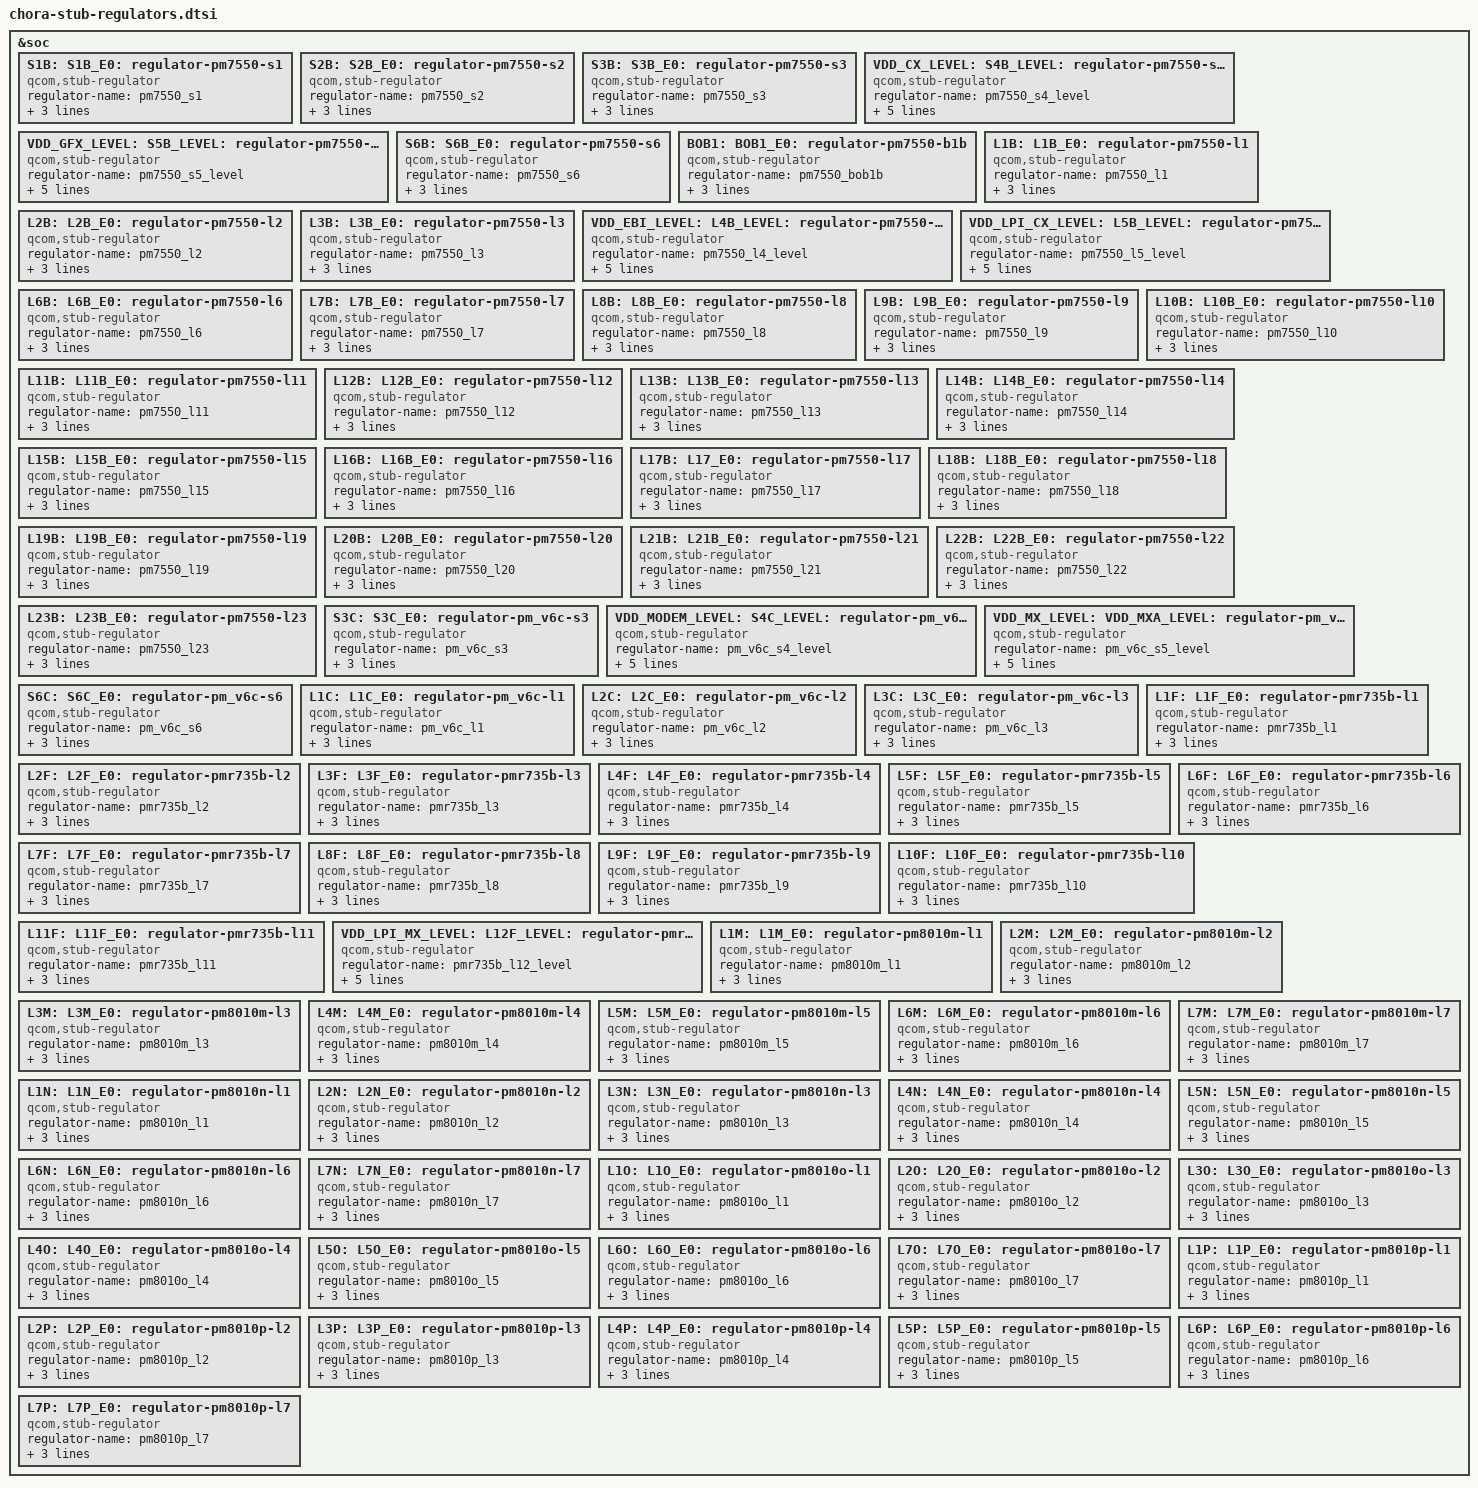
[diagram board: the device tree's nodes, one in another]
// SPDX-License-Identifier: BSD-3-Clause
/*
 * Copyright (c) Qualcomm Technologies, Inc. and/or its subsidiaries.
 */

#include <dt-bindings/regulator/qcom,rpmh-regulator-levels.h>

&soc {
		S1B:
		S1B_E0:
		pm7550_s1: regulator-pm7550-s1 {
			compatible = "qcom,stub-regulator";
			regulator-name = "pm7550_s1";
			qcom,hpm-min-load = <10000>;
			regulator-min-microvolt = <1856000>;
			regulator-max-microvolt = <2040000>;
		};

		S2B:
		S2B_E0:
		pm7550_s2: regulator-pm7550-s2 {
			compatible = "qcom,stub-regulator";
			regulator-name = "pm7550_s2";
			qcom,hpm-min-load = <10000>;
			regulator-min-microvolt = <1020000>;
			regulator-max-microvolt = <2100000>;
		};

		S3B:
		S3B_E0:
		pm7550_s3: regulator-pm7550-s3 {
			compatible = "qcom,stub-regulator";
			regulator-name = "pm7550_s3";
			qcom,hpm-min-load = <10000>;
			regulator-min-microvolt = <375000>;
			regulator-max-microvolt = <2744000>;
		};

		VDD_CX_LEVEL:
		S4B_LEVEL:
		S4B_E0_LEVEL:
		VDD_CX_LEVEL_AO:
		S4B_LEVEL_A0:
		pm7550_s4_level: regulator-pm7550-s4-level {
			compatible = "qcom,stub-regulator";
			regulator-name = "pm7550_s4_level";
			qcom,hpm-min-load = <10000>;
			regulator-min-microvolt =
				<RPMH_REGULATOR_LEVEL_RETENTION>;
			regulator-max-microvolt = <RPMH_REGULATOR_LEVEL_MAX>;
		};

		VDD_GFX_LEVEL:
		S5B_LEVEL:
		S5B_E0_LEVEL:
		pm7550_s5_level: regulator-pm7550-s5-level {
			compatible = "qcom,stub-regulator";
			regulator-name = "pm7550_s5_level";
			qcom,hpm-min-load = <10000>;
			regulator-min-microvolt =
				<RPMH_REGULATOR_LEVEL_RETENTION>;
			regulator-max-microvolt = <RPMH_REGULATOR_LEVEL_MAX>;
		};

		S6B:
		S6B_E0:
		pm7550_s6: regulator-pm7550-s6 {
			compatible = "qcom,stub-regulator";
			regulator-name = "pm7550_s6";
			qcom,hpm-min-load = <10000>;
			regulator-min-microvolt = <300000>;
			regulator-max-microvolt = <650000>;
		};

		BOB1:
		BOB1_E0:
		pm7550_b1b: regulator-pm7550-b1b {
			compatible = "qcom,stub-regulator";
			regulator-name = "pm7550_bob1b";
			qcom,hpm-min-load = <10000>;
			regulator-min-microvolt = <2500000>;
			regulator-max-microvolt = <4500000>;
		};

		L1B:
		L1B_E0:
		pm7550_l1: regulator-pm7550-l1 {
			compatible = "qcom,stub-regulator";
			regulator-name = "pm7550_l1";
			qcom,hpm-min-load = <10000>;
			regulator-min-microvolt = <1100000>;
			regulator-max-microvolt = <1980000>;
		};

		L2B:
		L2B_E0:
		pm7550_l2: regulator-pm7550-l2 {
			compatible = "qcom,stub-regulator";
			regulator-name = "pm7550_l2";
			qcom,hpm-min-load = <10000>;
			regulator-min-microvolt = <720000>;
			regulator-max-microvolt = <958000>;
		};

		L3B:
		L3B_E0:
		pm7550_l3: regulator-pm7550-l3 {
			compatible = "qcom,stub-regulator";
			regulator-name = "pm7550_l3";
			qcom,hpm-min-load = <10000>;
			regulator-min-microvolt = <870000>;
			regulator-max-microvolt = <970000>;
		};

		VDD_EBI_LEVEL:
		L4B_LEVEL:
		L4B_E0_LEVEL:
		pm7550_l4_level: regulator-pm7550-l4-level {
			compatible = "qcom,stub-regulator";
			regulator-name = "pm7550_l4_level";
			qcom,hpm-min-load = <10000>;
			regulator-min-microvolt =
				<RPMH_REGULATOR_LEVEL_RETENTION>;
			regulator-max-microvolt = <RPMH_REGULATOR_LEVEL_MAX>;
		};

		VDD_LPI_CX_LEVEL:
		L5B_LEVEL:
		L5B_E0_LEVEL:
		pm7550_l5_level: regulator-pm7550-l5-level {
			compatible = "qcom,stub-regulator";
			regulator-name = "pm7550_l5_level";
			qcom,hpm-min-load = <10000>;
			regulator-min-microvolt =
				<RPMH_REGULATOR_LEVEL_RETENTION>;
			regulator-max-microvolt = <RPMH_REGULATOR_LEVEL_MAX>;
		};

		L6B:
		L6B_E0:
		pm7550_l6: regulator-pm7550-l6 {
			compatible = "qcom,stub-regulator";
			regulator-name = "pm7550_l6";
			qcom,hpm-min-load = <10000>;
			regulator-min-microvolt = <1170000>;
			regulator-max-microvolt = <1370000>;
		};

		L7B:
		L7B_E0:
		pm7550_l7: regulator-pm7550-l7 {
			compatible = "qcom,stub-regulator";
			regulator-name = "pm7550_l7";
			qcom,hpm-min-load = <10000>;
			regulator-min-microvolt = <1080000>;
			regulator-max-microvolt = <2000000>;
		};

		L8B:
		L8B_E0:
		pm7550_l8: regulator-pm7550-l8 {
			compatible = "qcom,stub-regulator";
			regulator-name = "pm7550_l8";
			qcom,hpm-min-load = <10000>;
			regulator-min-microvolt = <320000>;
			regulator-max-microvolt = <2000000>;
		};

		L9B:
		L9B_E0:
		pm7550_l9: regulator-pm7550-l9 {
			compatible = "qcom,stub-regulator";
			regulator-name = "pm7550_l9";
			qcom,hpm-min-load = <10000>;
			regulator-min-microvolt = <1650000>;
			regulator-max-microvolt = <2000000>;
		};

		L10B:
		L10B_E0:
		pm7550_l10: regulator-pm7550-l10 {
			compatible = "qcom,stub-regulator";
			regulator-name = "pm7550_l10";
			qcom,hpm-min-load = <10000>;
			regulator-min-microvolt = <1080000>;
			regulator-max-microvolt = <2000000>;
		};

		L11B:
		L11B_E0:
		pm7550_l11: regulator-pm7550-l11 {
			compatible = "qcom,stub-regulator";
			regulator-name = "pm7550_l11";
			qcom,hpm-min-load = <10000>;
			regulator-min-microvolt = <1080000>;
			regulator-max-microvolt = <1320000>;
		};

		L12B:
		L12B_E0:
		pm7550_l12: regulator-pm7550-l12 {
			compatible = "qcom,stub-regulator";
			regulator-name = "pm7550_l12";
			qcom,hpm-min-load = <10000>;
			regulator-min-microvolt = <2400000>;
			regulator-max-microvolt = <3300000>;
		};

		L13B:
		L13B_E0:
		pm7550_l13: regulator-pm7550-l13 {
			compatible = "qcom,stub-regulator";
			regulator-name = "pm7550_l13";
			qcom,hpm-min-load = <10000>;
			regulator-min-microvolt = <2700000>;
			regulator-max-microvolt = <3300000>;
		};

		L14B:
		L14B_E0:
		pm7550_l14: regulator-pm7550-l14 {
			compatible = "qcom,stub-regulator";
			regulator-name = "pm7550_l14";
			qcom,hpm-min-load = <10000>;
			regulator-min-microvolt = <3125000>;
			regulator-max-microvolt = <3465000>;
		};

		L15B:
		L15B_E0:
		pm7550_l15: regulator-pm7550-l15 {
			compatible = "qcom,stub-regulator";
			regulator-name = "pm7550_l15";
			qcom,hpm-min-load = <10000>;
			regulator-min-microvolt = <3125000>;
			regulator-max-microvolt = <3465000>;
		};

		L16B:
		L16B_E0:
		pm7550_l16: regulator-pm7550-l16 {
			compatible = "qcom,stub-regulator";
			regulator-name = "pm7550_l16";
			qcom,hpm-min-load = <10000>;
			regulator-min-microvolt = <2900000>;
			regulator-max-microvolt = <3544000>;
		};

		L17B:
		L17_E0:
		pm7550_l17: regulator-pm7550-l17 {
			compatible = "qcom,stub-regulator";
			regulator-name = "pm7550_l17";
			qcom,hpm-min-load = <10000>;
			regulator-min-microvolt = <2700000>;
			regulator-max-microvolt = <3544000>;
		};

		L18B:
		L18B_E0:
		pm7550_l18: regulator-pm7550-l18 {
			compatible = "qcom,stub-regulator";
			regulator-name = "pm7550_l18";
			qcom,hpm-min-load = <10000>;
			regulator-min-microvolt = <1600000>;
			regulator-max-microvolt = <3544000>;
		};

		L19B:
		L19B_E0:
		pm7550_l19: regulator-pm7550-l19 {
			compatible = "qcom,stub-regulator";
			regulator-name = "pm7550_l19";
			qcom,hpm-min-load = <10000>;
			regulator-min-microvolt = <2600000>;
			regulator-max-microvolt = <3544000>;
		};

		L20B:
		L20B_E0:
		pm7550_l20: regulator-pm7550-l20 {
			compatible = "qcom,stub-regulator";
			regulator-name = "pm7550_l20";
			qcom,hpm-min-load = <10000>;
			regulator-min-microvolt = <1504000>;
			regulator-max-microvolt = <3544000>;
		};

		L21B:
		L21B_E0:
		pm7550_l21: regulator-pm7550-l21 {
			compatible = "qcom,stub-regulator";
			regulator-name = "pm7550_l21";
			qcom,hpm-min-load = <10000>;
			regulator-min-microvolt = <1504000>;
			regulator-max-microvolt = <3544000>;
		};

		L22B:
		L22B_E0:
		pm7550_l22: regulator-pm7550-l22 {
			compatible = "qcom,stub-regulator";
			regulator-name = "pm7550_l22";
			qcom,hpm-min-load = <10000>;
			regulator-min-microvolt = <2700000>;
			regulator-max-microvolt = <3400000>;
		};

		L23B:
		L23B_E0:
		pm7550_l23: regulator-pm7550-l23 {
			compatible = "qcom,stub-regulator";
			regulator-name = "pm7550_l23";
			qcom,hpm-min-load = <10000>;
			regulator-min-microvolt = <1650000>;
			regulator-max-microvolt = <3544000>;
		};

		S3C:
		S3C_E0:
		pm_v6c_s3: regulator-pm_v6c-s3 {
			compatible = "qcom,stub-regulator";
			regulator-name = "pm_v6c_s3";
			qcom,hpm-min-load = <10000>;
			regulator-min-microvolt = <1010000>;
			regulator-max-microvolt = <1170000>;
		};

		VDD_MODEM_LEVEL:
		S4C_LEVEL:
		S4C_E0_LEVEL:
		pm_v6c_s4_level: regulator-pm_v6c-s4-level {
			compatible = "qcom,stub-regulator";
			regulator-name = "pm_v6c_s4_level";
			qcom,hpm-min-load = <10000>;
			regulator-min-microvolt =
				<RPMH_REGULATOR_LEVEL_RETENTION>;
			regulator-max-microvolt = <RPMH_REGULATOR_LEVEL_MAX>;
		};

		VDD_MX_LEVEL:
		VDD_MXA_LEVEL:
		S5C_LEVEL:
		S5C_E0_LEVEL:
		VDD_MX_LEVEL_AO:
		S5C_LEVEL_A0:
		pm_v6c_s5_level: regulator-pm_v6c-s5-level {
			compatible = "qcom,stub-regulator";
			regulator-name = "pm_v6c_s5_level";
			qcom,hpm-min-load = <10000>;
			regulator-min-microvolt =
				<RPMH_REGULATOR_LEVEL_RETENTION>;
			regulator-max-microvolt = <RPMH_REGULATOR_LEVEL_MAX>;
		};

		S6C:
		S6C_E0:
		pm_v6c_s6: regulator-pm_v6c-s6 {
			compatible = "qcom,stub-regulator";
			regulator-name = "pm_v6c_s6";
			qcom,hpm-min-load = <10000>;
			regulator-min-microvolt = <572000>;
			regulator-max-microvolt = <856000>;
		};

		L1C:
		L1C_E0:
		pm_v6c_l1: regulator-pm_v6c-l1 {
			compatible = "qcom,stub-regulator";
			regulator-name = "pm_v6c_l1";
			qcom,hpm-min-load = <10000>;
			regulator-min-microvolt = <320000>;
			regulator-max-microvolt = <650000>;
		};

		L2C:
		L2C_E0:
		pm_v6c_l2: regulator-pm_v6c-l2 {
			compatible = "qcom,stub-regulator";
			regulator-name = "pm_v6c_l2";
			qcom,hpm-min-load = <10000>;
			regulator-min-microvolt = <1140000>;
			regulator-max-microvolt = <1260000>;
		};

		L3C:
		L3C_E0:
		pm_v6c_l3: regulator-pm_v6c-l3 {
			compatible = "qcom,stub-regulator";
			regulator-name = "pm_v6c_l3";
			qcom,hpm-min-load = <10000>;
			regulator-min-microvolt = <1080000>;
			regulator-max-microvolt = <1320000>;
		};

		L1F:
		L1F_E0:
		pmr735b_l1: regulator-pmr735b-l1 {
			compatible = "qcom,stub-regulator";
			regulator-name = "pmr735b_l1";
			qcom,hpm-min-load = <10000>;
			regulator-min-microvolt = <852000>;
			regulator-max-microvolt = <950000>;
		};

		L2F:
		L2F_E0:
		pmr735b_l2: regulator-pmr735b-l2 {
			compatible = "qcom,stub-regulator";
			regulator-name = "pmr735b_l2";
			qcom,hpm-min-load = <10000>;
			regulator-min-microvolt = <751000>;
			regulator-max-microvolt = <824000>;
		};

		L3F:
		L3F_E0:
		pmr735b_l3: regulator-pmr735b-l3 {
			compatible = "qcom,stub-regulator";
			regulator-name = "pmr735b_l3";
			qcom,hpm-min-load = <10000>;
			regulator-min-microvolt = <620000>;
			regulator-max-microvolt = <1050000>;
		};

		L4F:
		L4F_E0:
		pmr735b_l4: regulator-pmr735b-l4 {
			compatible = "qcom,stub-regulator";
			regulator-name = "pmr735b_l4";
			qcom,hpm-min-load = <10000>;
			regulator-min-microvolt = <1600000>;
			regulator-max-microvolt = <2000000>;
		};

		L5F:
		L5F_E0:
		pmr735b_l5: regulator-pmr735b-l5 {
			compatible = "qcom,stub-regulator";
			regulator-name = "pmr735b_l5";
			qcom,hpm-min-load = <10000>;
			regulator-min-microvolt = <1000000>;
			regulator-max-microvolt = <1304000>;
		};

		L6F:
		L6F_E0:
		pmr735b_l6: regulator-pmr735b-l6 {
			compatible = "qcom,stub-regulator";
			regulator-name = "pmr735b_l6";
			qcom,hpm-min-load = <10000>;
			regulator-min-microvolt = <1150000>;
			regulator-max-microvolt = <1250000>;
		};

		L7F:
		L7F_E0:
		pmr735b_l7: regulator-pmr735b-l7 {
			compatible = "qcom,stub-regulator";
			regulator-name = "pmr735b_l7";
			qcom,hpm-min-load = <10000>;
			regulator-min-microvolt = <1080000>;
			regulator-max-microvolt = <1304000>;
		};

		L8F:
		L8F_E0:
		pmr735b_l8: regulator-pmr735b-l8 {
			compatible = "qcom,stub-regulator";
			regulator-name = "pmr735b_l8";
			qcom,hpm-min-load = <10000>;
			regulator-min-microvolt = <1100000>;
			regulator-max-microvolt = <1304000>;
		};

		L9F:
		L9F_E0:
		pmr735b_l9: regulator-pmr735b-l9 {
			compatible = "qcom,stub-regulator";
			regulator-name = "pmr735b_l9";
			qcom,hpm-min-load = <10000>;
			regulator-min-microvolt = <1080000>;
			regulator-max-microvolt = <1304000>;
		};

		L10F:
		L10F_E0:
		pmr735b_l10: regulator-pmr735b-l10 {
			compatible = "qcom,stub-regulator";
			regulator-name = "pmr735b_l10";
			qcom,hpm-min-load = <10000>;
			regulator-min-microvolt = <1504000>;
			regulator-max-microvolt = <2000000>;
		};

		L11F:
		L11F_E0:
		pmr735b_l11: regulator-pmr735b-l11 {
			compatible = "qcom,stub-regulator";
			regulator-name = "pmr735b_l11";
			qcom,hpm-min-load = <10000>;
			regulator-min-microvolt = <504000>;
			regulator-max-microvolt = <864000>;
		};

		VDD_LPI_MX_LEVEL:
		L12F_LEVEL:
		L12F_E0_LEVEL:
		pmr735b_l12_level: regulator-pmr735b-l12-level {
			compatible = "qcom,stub-regulator";
			regulator-name = "pmr735b_l12_level";
			qcom,hpm-min-load = <10000>;
			regulator-min-microvolt =
				<RPMH_REGULATOR_LEVEL_RETENTION>;
			regulator-max-microvolt = <RPMH_REGULATOR_LEVEL_MAX>;
		};

		L1M:
		L1M_E0:
		pm8010m_l1: regulator-pm8010m-l1 {
			compatible = "qcom,stub-regulator";
			regulator-name = "pm8010m_l1";
			qcom,hpm-min-load = <10000>;
			regulator-min-microvolt = <1050000>;
			regulator-max-microvolt = <1180000>;
		};

		L2M:
		L2M_E0:
		pm8010m_l2: regulator-pm8010m-l2 {
			compatible = "qcom,stub-regulator";
			regulator-name = "pm8010m_l2";
			qcom,hpm-min-load = <10000>;
			regulator-min-microvolt = <950000>;
			regulator-max-microvolt = <1150000>;
		};

		L3M:
		L3M_E0:
		pm8010m_l3: regulator-pm8010m-l3 {
			compatible = "qcom,stub-regulator";
			regulator-name = "pm8010m_l3";
			qcom,hpm-min-load = <10000>;
			regulator-min-microvolt = <2700000>;
			regulator-max-microvolt = <2900000>;
		};

		L4M:
		L4M_E0:
		pm8010m_l4: regulator-pm8010m-l4 {
			compatible = "qcom,stub-regulator";
			regulator-name = "pm8010m_l4";
			qcom,hpm-min-load = <10000>;
			regulator-min-microvolt = <2700000>;
			regulator-max-microvolt = <2900000>;
		};

		L5M:
		L5M_E0:
		pm8010m_l5: regulator-pm8010m-l5 {
			compatible = "qcom,stub-regulator";
			regulator-name = "pm8010m_l5";
			qcom,hpm-min-load = <10000>;
			regulator-min-microvolt = <1504000>;
			regulator-max-microvolt = <3544000>;
		};

		L6M:
		L6M_E0:
		pm8010m_l6: regulator-pm8010m-l6 {
			compatible = "qcom,stub-regulator";
			regulator-name = "pm8010m_l6";
			qcom,hpm-min-load = <10000>;
			regulator-min-microvolt = <2700000>;
			regulator-max-microvolt = <2900000>;
		};

		L7M:
		L7M_E0:
		pm8010m_l7: regulator-pm8010m-l7 {
			compatible = "qcom,stub-regulator";
			regulator-name = "pm8010m_l7";
			qcom,hpm-min-load = <10000>;
			regulator-min-microvolt = <2700000>;
			regulator-max-microvolt = <3000000>;
		};

		L1N:
		L1N_E0:
		pm8010n_l1: regulator-pm8010n-l1 {
			compatible = "qcom,stub-regulator";
			regulator-name = "pm8010n_l1";
			qcom,hpm-min-load = <10000>;
			regulator-min-microvolt = <1050000>;
			regulator-max-microvolt = <1200000>;
		};

		L2N:
		L2N_E0:
		pm8010n_l2: regulator-pm8010n-l2 {
			compatible = "qcom,stub-regulator";
			regulator-name = "pm8010n_l2";
			qcom,hpm-min-load = <10000>;
			regulator-min-microvolt = <950000>;
			regulator-max-microvolt = <1150000>;
		};

		L3N:
		L3N_E0:
		pm8010n_l3: regulator-pm8010n-l3 {
			compatible = "qcom,stub-regulator";
			regulator-name = "pm8010n_l3";
			qcom,hpm-min-load = <10000>;
			regulator-min-microvolt = <1792000>;
			regulator-max-microvolt = <1900000>;
		};

		L4N:
		L4N_E0:
		pm8010n_l4: regulator-pm8010n-l4 {
			compatible = "qcom,stub-regulator";
			regulator-name = "pm8010n_l4";
			qcom,hpm-min-load = <10000>;
			regulator-min-microvolt = <1792000>;
			regulator-max-microvolt = <1900000>;
		};

		L5N:
		L5N_E0:
		pm8010n_l5: regulator-pm8010n-l5 {
			compatible = "qcom,stub-regulator";
			regulator-name = "pm8010n_l5";
			qcom,hpm-min-load = <10000>;
			regulator-min-microvolt = <1620000>;
			regulator-max-microvolt = <1980000>;
		};

		L6N:
		L6N_E0:
		pm8010n_l6: regulator-pm8010n-l6 {
			compatible = "qcom,stub-regulator";
			regulator-name = "pm8010n_l6";
			qcom,hpm-min-load = <10000>;
			regulator-min-microvolt = <2700000>;
			regulator-max-microvolt = <2900000>;
		};

		L7N:
		L7N_E0:
		pm8010n_l7: regulator-pm8010n-l7 {
			compatible = "qcom,stub-regulator";
			regulator-name = "pm8010n_l7";
			qcom,hpm-min-load = <10000>;
			regulator-min-microvolt = <2500000>;
			regulator-max-microvolt = <3300000>;
		};

		L1O:
		L1O_E0:
		pm8010o_l1: regulator-pm8010o-l1 {
			compatible = "qcom,stub-regulator";
			regulator-name = "pm8010o_l1";
			qcom,hpm-min-load = <10000>;
			regulator-min-microvolt = <1050000>;
			regulator-max-microvolt = <1180000>;
		};

		L2O:
		L2O_E0:
		pm8010o_l2: regulator-pm8010o-l2 {
			compatible = "qcom,stub-regulator";
			regulator-name = "pm8010o_l2";
			qcom,hpm-min-load = <10000>;
			regulator-min-microvolt = <950000>;
			regulator-max-microvolt = <1150000>;
		};

		L3O:
		L3O_E0:
		pm8010o_l3: regulator-pm8010o-l3 {
			compatible = "qcom,stub-regulator";
			regulator-name = "pm8010o_l3";
			qcom,hpm-min-load = <10000>;
			regulator-min-microvolt = <2700000>;
			regulator-max-microvolt = <2900000>;
		};

		L4O:
		L4O_E0:
		pm8010o_l4: regulator-pm8010o-l4 {
			compatible = "qcom,stub-regulator";
			regulator-name = "pm8010o_l4";
			qcom,hpm-min-load = <10000>;
			regulator-min-microvolt = <2700000>;
			regulator-max-microvolt = <2900000>;
		};

		L5O:
		L5O_E0:
		pm8010o_l5: regulator-pm8010o-l5 {
			compatible = "qcom,stub-regulator";
			regulator-name = "pm8010o_l5";
			qcom,hpm-min-load = <10000>;
			regulator-min-microvolt = <1504000>;
			regulator-max-microvolt = <3544000>;
		};

		L6O:
		L6O_E0:
		pm8010o_l6: regulator-pm8010o-l6 {
			compatible = "qcom,stub-regulator";
			regulator-name = "pm8010o_l6";
			qcom,hpm-min-load = <10000>;
			regulator-min-microvolt = <2700000>;
			regulator-max-microvolt = <2900000>;
		};

		L7O:
		L7O_E0:
		pm8010o_l7: regulator-pm8010o-l7 {
			compatible = "qcom,stub-regulator";
			regulator-name = "pm8010o_l7";
			qcom,hpm-min-load = <10000>;
			regulator-min-microvolt = <2700000>;
			regulator-max-microvolt = <3000000>;
		};

		L1P:
		L1P_E0:
		pm8010p_l1: regulator-pm8010p-l1 {
			compatible = "qcom,stub-regulator";
			regulator-name = "pm8010p_l1";
			qcom,hpm-min-load = <10000>;
			regulator-min-microvolt = <1050000>;
			regulator-max-microvolt = <1200000>;
		};

		L2P:
		L2P_E0:
		pm8010p_l2: regulator-pm8010p-l2 {
			compatible = "qcom,stub-regulator";
			regulator-name = "pm8010p_l2";
			qcom,hpm-min-load = <10000>;
			regulator-min-microvolt = <950000>;
			regulator-max-microvolt = <1150000>;
		};

		L3P:
		L3P_E0:
		pm8010p_l3: regulator-pm8010p-l3 {
			compatible = "qcom,stub-regulator";
			regulator-name = "pm8010p_l3";
			qcom,hpm-min-load = <10000>;
			regulator-min-microvolt = <1700000>;
			regulator-max-microvolt = <1900000>;
		};

		L4P:
		L4P_E0:
		pm8010p_l4: regulator-pm8010p-l4 {
			compatible = "qcom,stub-regulator";
			regulator-name = "pm8010p_l4";
			qcom,hpm-min-load = <10000>;
			regulator-min-microvolt = <1700000>;
			regulator-max-microvolt = <1900000>;
		};

		L5P:
		L5P_E0:
		pm8010p_l5: regulator-pm8010p-l5 {
			compatible = "qcom,stub-regulator";
			regulator-name = "pm8010p_l5";
			qcom,hpm-min-load = <10000>;
			regulator-min-microvolt = <1620000>;
			regulator-max-microvolt = <1980000>;
		};

		L6P:
		L6P_E0:
		pm8010p_l6: regulator-pm8010p-l6 {
			compatible = "qcom,stub-regulator";
			regulator-name = "pm8010p_l6";
			qcom,hpm-min-load = <10000>;
			regulator-min-microvolt = <2700000>;
			regulator-max-microvolt = <2900000>;
		};

		L7P:
		L7P_E0:
		pm8010p_l7: regulator-pm8010p-l7 {
			compatible = "qcom,stub-regulator";
			regulator-name = "pm8010p_l7";
			qcom,hpm-min-load = <10000>;
			regulator-min-microvolt = <2500000>;
			regulator-max-microvolt = <3300000>;
		};
};
